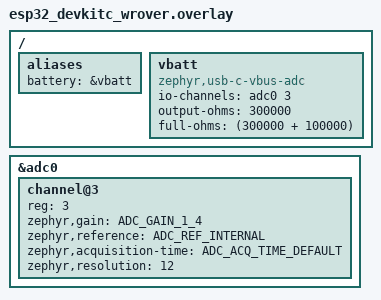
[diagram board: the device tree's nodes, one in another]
/*
 * Copyright (c) 2023 Mark Kettner <mark@kettner.io>
 *
 * SPDX-License-Identifier: Apache-2.0
 */

/ {
	aliases {
		battery = &vbatt;
	};

	vbatt: vbatt {
		compatible = "zephyr,usb-c-vbus-adc";
		status = "okay";
		io-channels = <&adc0 3>;
		output-ohms = <300000>;
		full-ohms = <(300000 + 100000)>;
	};

};

&adc0 {
	status = "okay";
	#address-cells = <1>;
	#size-cells = <0>;

	channel@3 {
		reg = <3>;
		zephyr,gain = "ADC_GAIN_1_4";
		zephyr,reference = "ADC_REF_INTERNAL";
		zephyr,acquisition-time = <ADC_ACQ_TIME_DEFAULT>;
		zephyr,resolution = <12>;
	};
};
